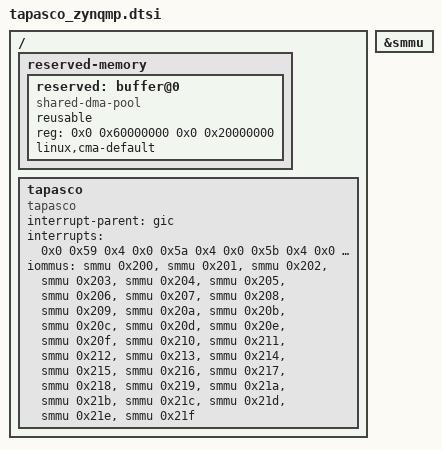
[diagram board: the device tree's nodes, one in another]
/ {
	reserved-memory {
		#address-cells = <2>;
		#size-cells = <2>;
		ranges;

		reserved: buffer@0 {
			compatible = "shared-dma-pool";
			reusable;
			reg = <0x0 0x60000000 0x0 0x20000000>;
			linux,cma-default;
		};
	};

	tapasco {
		compatible = "tapasco";
		interrupt-parent = <&gic>;
		interrupts = <0x0 0x59 0x4 0x0 0x5a 0x4 0x0 0x5b 0x4 0x0 0x5c 0x4 0x0 0x5d 0x4 0x0 0x5e 0x4 0x0 0x5f 0x4 0x0 0x60 0x4 0x0 0x68 0x4 0x0 0x69 0x4 0x0 0x6a 0x4 0x0 0x6b 0x4 0x0 0x6c 0x4 0x0 0x6d 0x4 0x0 0x6e 0x4 0x0 0x6f 0x4>;
		iommus = 
			<&smmu 0x200>,
			<&smmu 0x201>,
			<&smmu 0x202>,
			<&smmu 0x203>,
			<&smmu 0x204>,
			<&smmu 0x205>,
			<&smmu 0x206>,
			<&smmu 0x207>,
			<&smmu 0x208>,
			<&smmu 0x209>,
			<&smmu 0x20a>,
			<&smmu 0x20b>,
			<&smmu 0x20c>,
			<&smmu 0x20d>,
			<&smmu 0x20e>,
			<&smmu 0x20f>,
			<&smmu 0x210>,
			<&smmu 0x211>,
			<&smmu 0x212>,
			<&smmu 0x213>,
			<&smmu 0x214>,
			<&smmu 0x215>,
			<&smmu 0x216>,
			<&smmu 0x217>, 
			<&smmu 0x218>,
			<&smmu 0x219>,
			<&smmu 0x21a>,
			<&smmu 0x21b>,
			<&smmu 0x21c>,
			<&smmu 0x21d>,
			<&smmu 0x21e>,
			<&smmu 0x21f>;
	};
};

&smmu {
	status = "okay";
};
